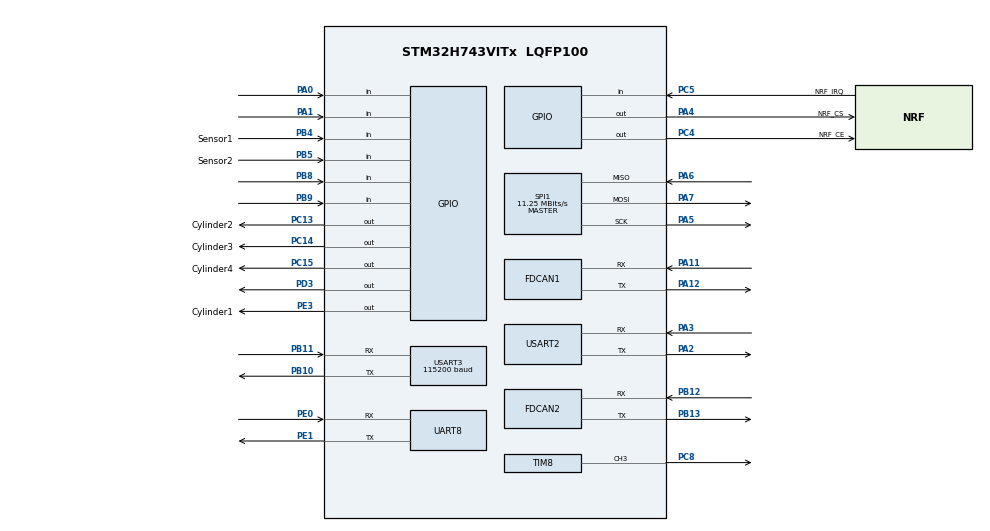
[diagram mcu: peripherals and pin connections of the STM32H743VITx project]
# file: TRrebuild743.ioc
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CORTEX_M7.CPU_DCache=Disabled
CORTEX_M7.CPU_ICache=Disabled
Dma.Request0=UART8_RX
Dma.Request1=TIM8_CH3
Dma.Request2=USART2_RX
Dma.TIM8_CH3.1.Direction=DMA_MEMORY_TO_PERIPH
Dma.TIM8_CH3.1.EventEnable=DISABLE
Dma.TIM8_CH3.1.FIFOMode=DMA_FIFOMODE_DISABLE
Dma.TIM8_CH3.1.Instance=DMA1_Stream1
Dma.TIM8_CH3.1.MemDataAlignment=DMA_MDATAALIGN_HALFWORD
Dma.TIM8_CH3.1.MemInc=DMA_MINC_ENABLE
Dma.TIM8_CH3.1.Mode=DMA_CIRCULAR
Dma.TIM8_CH3.1.PeriphDataAlignment=DMA_PDATAALIGN_HALFWORD
Dma.TIM8_CH3.1.PeriphInc=DMA_PINC_DISABLE
Dma.TIM8_CH3.1.Polarity=HAL_DMAMUX_REQ_GEN_RISING
Dma.TIM8_CH3.1.Priority=DMA_PRIORITY_HIGH
Dma.TIM8_CH3.1.RequestNumber=1
Dma.TIM8_CH3.1.SignalID=NONE
Dma.TIM8_CH3.1.SyncEnable=DISABLE
Dma.TIM8_CH3.1.SyncPolarity=HAL_DMAMUX_SYNC_NO_EVENT
Dma.TIM8_CH3.1.SyncRequestNumber=1
Dma.TIM8_CH3.1.SyncSignalID=NONE
Dma.UART8_RX.0.Direction=DMA_PERIPH_TO_MEMORY
Dma.UART8_RX.0.EventEnable=DISABLE
Dma.UART8_RX.0.FIFOMode=DMA_FIFOMODE_DISABLE
Dma.UART8_RX.0.Instance=DMA1_Stream0
Dma.UART8_RX.0.MemDataAlignment=DMA_MDATAALIGN_BYTE
Dma.UART8_RX.0.MemInc=DMA_MINC_ENABLE
Dma.UART8_RX.0.Mode=DMA_CIRCULAR
Dma.UART8_RX.0.PeriphDataAlignment=DMA_PDATAALIGN_BYTE
Dma.UART8_RX.0.PeriphInc=DMA_PINC_DISABLE
Dma.UART8_RX.0.Polarity=HAL_DMAMUX_REQ_GEN_RISING
Dma.UART8_RX.0.Priority=DMA_PRIORITY_LOW
Dma.UART8_RX.0.RequestNumber=1
Dma.UART8_RX.0.SignalID=NONE
Dma.UART8_RX.0.SyncEnable=DISABLE
Dma.UART8_RX.0.SyncPolarity=HAL_DMAMUX_SYNC_NO_EVENT
Dma.UART8_RX.0.SyncRequestNumber=1
Dma.UART8_RX.0.SyncSignalID=NONE
Dma.USART2_RX.2.Direction=DMA_PERIPH_TO_MEMORY
Dma.USART2_RX.2.EventEnable=DISABLE
Dma.USART2_RX.2.FIFOMode=DMA_FIFOMODE_DISABLE
Dma.USART2_RX.2.Instance=DMA1_Stream2
Dma.USART2_RX.2.MemDataAlignment=DMA_MDATAALIGN_BYTE
Dma.USART2_RX.2.MemInc=DMA_MINC_ENABLE
Dma.USART2_RX.2.Mode=DMA_CIRCULAR
Dma.USART2_RX.2.PeriphDataAlignment=DMA_PDATAALIGN_BYTE
Dma.USART2_RX.2.PeriphInc=DMA_PINC_DISABLE
Dma.USART2_RX.2.Polarity=HAL_DMAMUX_REQ_GEN_RISING
Dma.USART2_RX.2.Priority=DMA_PRIORITY_LOW
Dma.USART2_RX.2.RequestNumber=1
Dma.USART2_RX.2.SignalID=NONE
Dma.USART2_RX.2.SyncEnable=DISABLE
Dma.USART2_RX.2.SyncPolarity=HAL_DMAMUX_SYNC_NO_EVENT
Dma.USART2_RX.2.SyncRequestNumber=1
Dma.USART2_RX.2.SyncSignalID=NONE
FDCAN1.DataTimeSeg1=15
FDCAN1.DataTimeSeg2=4
FDCAN1.NominalSyncJumpWidth=1
FDCAN1.NominalTimeSeg1=15
FDCAN1.NominalTimeSeg2=4
FDCAN1.RxFifo0ElmtsNbr=32
FDCAN1.StdFiltersNbr=1
FDCAN1.TxBuffersNbr=0
FDCAN1.TxFifoQueueElmtsNbr=16
FDCAN2.AutoRetransmission=DISABLE
FDCAN2.DataTimeSeg1=15
FDCAN2.DataTimeSeg2=4
FDCAN2.MessageRAMOffset=0x304
FDCAN2.NominalTimeSeg1=15
FDCAN2.NominalTimeSeg2=4
FDCAN2.RxFifo1ElmtsNbr=32
FDCAN2.StdFiltersNbr=2
FDCAN2.TxFifoQueueElmtsNbr=16
FREERTOS.INCLUDE_xTaskGetHandle=1
FREERTOS.Tasks01=defaultTask,24,128,StartDefaultTask,Default,NULL,Dynamic,NULL,NULL;Robot,24,256,RobotTask,Default,NULL,Dynamic,NULL,NULL;manualmove,8,256,manual_move,Default,NULL,Dynamic,NULL,NULL;error_detector,8,128,errordetector,Default,NULL,Dynamic,NULL,NULL;debug_msg,8,128,send_debug_msg,Default,NULL,Dynamic,NULL,NULL
FREERTOS.configTOTAL_HEAP_SIZE=0x2C000
Mcu.Family=STM32H7
Mcu.Name=STM32H743VITx
Mcu.Package=LQFP100
NVIC.DMA1_Stream0_IRQn=true\:5\:0\:false\:false\:true\:true\:false\:true
NVIC.DMA1_Stream1_IRQn=true\:5\:0\:false\:false\:true\:true\:false\:true
NVIC.DMA1_Stream2_IRQn=true\:5\:0\:false\:false\:true\:true\:false\:true
NVIC.FDCAN1_IT0_IRQn=true\:5\:0\:true\:false\:true\:true\:true\:true
NVIC.FDCAN2_IT0_IRQn=true\:5\:0\:false\:false\:true\:true\:true\:true
NVIC.PriorityGroup=NVIC_PRIORITYGROUP_4
NVIC.TIM6_DAC_IRQn=true\:5\:0\:true\:false\:true\:true\:true\:true
NVIC.TIM7_IRQn=true\:1\:0\:true\:false\:true\:false\:true\:true
NVIC.TIM8_BRK_TIM12_IRQn=true\:5\:0\:false\:false\:true\:true\:true\:true
NVIC.TIM8_TRG_COM_TIM14_IRQn=true\:5\:0\:false\:false\:true\:false\:false\:true
NVIC.TIM8_UP_TIM13_IRQn=true\:5\:0\:false\:false\:true\:true\:true\:true
NVIC.TimeBase=TIM8_TRG_COM_TIM14_IRQn
NVIC.TimeBaseIP=TIM14
NVIC.UART8_IRQn=true\:5\:0\:false\:false\:true\:true\:true\:true
NVIC.USART3_IRQn=true\:5\:0\:false\:false\:true\:true\:true\:true
PA0.GPIO_PuPd=GPIO_PULLDOWN
PA0.Signal=GPIO_Input
PA1.GPIO_PuPd=GPIO_PULLDOWN
PA1.Signal=GPIO_Input
PA11.GPIO_PuPd=GPIO_PULLUP
PA11.GPIO_Speed=GPIO_SPEED_FREQ_VERY_HIGH
PA11.Mode=FDCAN_Activate
PA11.Signal=FDCAN1_RX
PA12.GPIO_PuPd=GPIO_PULLUP
PA12.GPIO_Speed=GPIO_SPEED_FREQ_VERY_HIGH
PA12.Mode=FDCAN_Activate
PA12.Signal=FDCAN1_TX
PA13\ (JTMS/SWDIO).Mode=Serial_Wire
PA13\ (JTMS/SWDIO).Signal=DEBUG_JTMS-SWDIO
PA14\ (JTCK/SWCLK).Mode=Serial_Wire
PA14\ (JTCK/SWCLK).Signal=DEBUG_JTCK-SWCLK
PA2.Mode=Asynchronous
PA2.Signal=USART2_TX
PA3.Mode=Asynchronous
PA3.Signal=USART2_RX
PA4.GPIO_Label=NRF_CS
PA4.GPIO_PuPd=GPIO_PULLUP
PA4.GPIO_Speed=GPIO_SPEED_FREQ_HIGH
PA4.Signal=GPIO_Output
PA5.GPIO_PuPd=GPIO_NOPULL
PA5.GPIO_Speed=GPIO_SPEED_FREQ_VERY_HIGH
PA5.Mode=Full_Duplex_Master
PA5.Signal=SPI1_SCK
PA6.GPIO_PuPd=GPIO_NOPULL
PA6.GPIO_Speed=GPIO_SPEED_FREQ_VERY_HIGH
PA6.Mode=Full_Duplex_Master
PA6.Signal=SPI1_MISO
PA7.GPIO_PuPd=GPIO_NOPULL
PA7.GPIO_Speed=GPIO_SPEED_FREQ_VERY_HIGH
PA7.Mode=Full_Duplex_Master
PA7.Signal=SPI1_MOSI
PB10.Mode=Asynchronous
PB10.Signal=USART3_TX
PB11.Mode=Asynchronous
PB11.Signal=USART3_RX
PB12.GPIO_PuPd=GPIO_PULLUP
PB12.GPIO_Speed=GPIO_SPEED_FREQ_VERY_HIGH
PB12.Mode=FDCAN_Activate
PB12.Signal=FDCAN2_RX
PB13.GPIO_PuPd=GPIO_PULLUP
PB13.GPIO_Speed=GPIO_SPEED_FREQ_VERY_HIGH
PB13.Mode=FDCAN_Activate
PB13.Signal=FDCAN2_TX
PB4\ (NJTRST).GPIO_Label=Sensor1
PB4\ (NJTRST).GPIO_PuPd=GPIO_PULLDOWN
PB4\ (NJTRST).Signal=GPIO_Input
PB5.GPIO_Label=Sensor2
PB5.GPIO_PuPd=GPIO_PULLDOWN
PB5.Signal=GPIO_Input
PB8.GPIO_PuPd=GPIO_PULLDOWN
PB8.Signal=GPIO_Input
PB9.GPIO_PuPd=GPIO_PULLDOWN
PB9.Signal=GPIO_Input
PC13.GPIO_Label=Cylinder2
PC13.GPIO_PuPd=GPIO_PULLUP
PC13.Signal=GPIO_Output
PC14-OSC32_IN\ (OSC32_IN).GPIO_Label=Cylinder3
PC14-OSC32_IN\ (OSC32_IN).GPIO_PuPd=GPIO_PULLUP
PC14-OSC32_IN\ (OSC32_IN).Signal=GPIO_Output
PC15-OSC32_OUT\ (OSC32_OUT).GPIO_Label=Cylinder4
PC15-OSC32_OUT\ (OSC32_OUT).GPIO_PuPd=GPIO_PULLUP
PC15-OSC32_OUT\ (OSC32_OUT).Signal=GPIO_Output
PC4.GPIO_Label=NRF_CE
PC4.GPIO_PuPd=GPIO_PULLUP
PC4.GPIO_Speed=GPIO_SPEED_FREQ_HIGH
PC4.Signal=GPIO_Output
PC5.GPIO_Label=NRF_IRQ
PC5.Signal=GPIO_Input
PC8.GPIO_Speed=GPIO_SPEED_FREQ_VERY_HIGH
PC8.Signal=S_TIM8_CH3
PD3.GPIO_PuPd=GPIO_PULLDOWN
PD3.GPIO_Speed=GPIO_SPEED_FREQ_HIGH
PD3.Signal=GPIO_Output
PE0.Mode=Asynchronous
PE0.Signal=UART8_RX
PE1.Mode=Asynchronous
PE1.Signal=UART8_TX
PE3.GPIO_Label=Cylinder1
PE3.GPIO_PuPd=GPIO_PULLUP
PE3.Signal=GPIO_Output
PH0-OSC_IN\ (PH0).Mode=HSE-External-Oscillator
PH0-OSC_IN\ (PH0).Signal=RCC_OSC_IN
PH1-OSC_OUT\ (PH1).Mode=HSE-External-Oscillator
PH1-OSC_OUT\ (PH1).Signal=RCC_OSC_OUT
ProjectManager.HeapSize=0x3F000
ProjectManager.StackSize=0x2000
ProjectManager.TargetToolchain=MDK-ARM V5.27
RCC.ADCFreq_Value=90000000
RCC.APB1Freq_Value=120000000
RCC.APB2Freq_Value=120000000
RCC.APB3Freq_Value=120000000
RCC.APB4Freq_Value=120000000
RCC.CortexFreq_Value=480000000
RCC.D1PPRE=RCC_APB3_DIV2
RCC.D2PPRE1=RCC_APB1_DIV2
RCC.D2PPRE2=RCC_APB2_DIV2
RCC.D3PPRE=RCC_APB4_DIV2
RCC.DIVM1=5
RCC.DIVM2=5
RCC.DIVN1=192
RCC.DIVN2=90
RCC.DIVP2=5
RCC.DIVQ1=48
RCC.HCLKFreq_Value=240000000
RCC.HPRE=RCC_HCLK_DIV2
RCC.PLL2FRACN=0
RCC.PLL3FRACN=0
RCC.PLLFRACN=0
RCC.PLLSourceVirtual=RCC_PLLSOURCE_HSE
RCC.SPI123CLockSelection=RCC_SPI123CLKSOURCE_PLL2
RCC.SYSCLKFreq_VALUE=480000000
RCC.SYSCLKSource=RCC_SYSCLKSOURCE_PLLCLK
RCC.USBFreq_Value=20000000
SH.S_TIM8_CH3.0=TIM8_CH3,PWM Generation3 CH3
SPI1.BaudRatePrescaler=SPI_BAUDRATEPRESCALER_8
SPI1.CalculateBaudRate=11.25 MBits/s
SPI1.DataSize=SPI_DATASIZE_8BIT
SPI1.Direction=SPI_DIRECTION_2LINES
SPI1.Mode=SPI_MODE_MASTER
SPI1.VirtualType=VM_MASTER
TIM6.Period=9999
TIM6.Prescaler=239
TIM7.Period=100-1
TIM7.Prescaler=240-1
TIM8.AutoReloadPreload=TIM_AUTORELOAD_PRELOAD_DISABLE
TIM8.Channel-PWM\ Generation3\ CH3=TIM_CHANNEL_3
TIM8.Period=75-1
TIM8.Prescaler=4-1
USART2.VirtualMode-Asynchronous=VM_ASYNC
USART3.BaudRate=115200
USART3.VirtualMode-Asynchronous=VM_ASYNC
VP_FREERTOS_VS_CMSIS_V2.Mode=CMSIS_V2
VP_SYS_VS_tim14.Mode=TIM14
VP_TIM6_VS_ClockSourceINT.Mode=Enable_Timer
VP_TIM7_VS_ClockSourceINT.Mode=Enable_Timer
VP_TIM8_VS_ClockSourceINT.Mode=Internal
board=custom

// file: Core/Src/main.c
/* USER CODE BEGIN Header */
/**
  ******************************************************************************
  * @file           : main.c
  * @brief          : Main program body
  ******************************************************************************
  * @attention
  *
  * <h2><center>&copy; Copyright (c) 2022 STMicroelectronics.
  * All rights reserved.</center></h2>
  *
  * This software component is licensed by ST under Ultimate Liberty license
  * SLA0044, the "License"; You may not use this file except in compliance with
  * the License. You may obtain a copy of the License at:
  *                             www.st.com/SLA0044
  *
  ******************************************************************************
  */
/* USER CODE END Header */
#include "main.h"
#include "cmsis_os.h"
#include "dma.h"
#include "fdcan.h"
#include "spi.h"
#include "tim.h"
#include "usart.h"
#include "gpio.h"

/* USER CODE BEGIN Includes */
#include "Elmo_fdcan.h"
#include "nrf.h"
#include "Resolve.h"
#include "fdcan_bsp.h"
#include "my_robot.h"
#include "math.h"
#include "usart.h"
#include "move.h"
#include "Remote_Control.h"
#include "arm_math.h"
#include "HMI.h"
#include "Tinn.h"
#include "rgb.h"
#include "GM6020.h"
#include "VESC_CAN.h"
#include "Ann.h"
#include "steering_wheel.h"
/* USER CODE END Includes */

/* USER CODE BEGIN PV */
extern Kal_Filter kal_velocity_x,kal_velocity_y;
extern float dX;
extern float dY;
extern float dZ;
Ort debug;
float last_pos_x=0,last_pos_y=0;
uint8_t rxtemp=0;
int rocker[4];
uint8_t turret_buffer[8];
uint8_t dma_buffer[30]={0};
uint8_t tof_buffer[10]={0};
short tof_read;
uint8_t Rx_buffer[16]={0};
uint8_t huart3_rxbuffer[16]={0};
Ort current_acceration;
Ort current_speed;
Ort current_chassis_speed,avg_speed;
Ort current_speed_before_filt;
Ort current_pos={.x=6,.y=0.41f};
Ort correction_value={.x=6,.y=0.335f};
uint8_t cmd_feedback[8];
Ort pos_buffer[9];
Ort speed_buffer[6];
Ort target_relative_pos;
int global_clock;
int speed_clock;
uint32_t speed_timer=0;
float vx[10],vy[10],ababa;
Ort pos_log[50];
uint8_t pos_reset=0;
ANN_PID_handle velocity_nn_x={.network.input_2_hidden.mat={0.07388,0,0.102044,0,0,0.102044,0,0.0574135,0,0,0.0574135,0,0.102044,0,0,0.10204422,0,-0.0063,0},.network.hidden_2_output.mat={0.073885,0,0.102044,0,0.0574135,0,0.10204422,0,-0.006343383}}
,velocity_nn_y={.network.input_2_hidden.mat={0.07388,0,0.102044,0,0,0.102044,0,0.0574135,0,0,0.0574135,0,0.102044,0,0,0.10204422,0,-0.0063,0},.network.hidden_2_output.mat={0.073885,0,0.102044,0,0.0574135,0,0.10204422,0,-0.006343383}};
Ort raw_correction_value;
uint8_t block_color=0;
uint8_t communciation_error_counter=0;
extern uint8_t get_block_flag;
//int package_recieve=0,package_valid=0;
//int start_nbr=0;

/* USER CODE END PV */

void SystemClock_Config(void);
void MX_FREERTOS_Init(void);
/* USER CODE BEGIN PFP */
void acceration_limit(void);
void speed_cal(void);
void update_target_info(uint8_t *data);
void DMA_recieve(void);
void executive_auto_move(void);
void send_log(uint8_t ID,float data1,float data2,float data3,float data4,UART_HandleTypeDef *uart);
void send_msg(void);
void send_init_msg(UART_HandleTypeDef *uart,uint8_t ID);
/* USER CODE END PFP */

int main(void)
{

  /* MCU Configuration--------------------------------------------------------*/

  /* Reset of all peripherals, Initializes the Flash interface and the Systick. */
  HAL_Init();

  /* Configure the system clock */
  SystemClock_Config();

  /* Initialize all configured peripherals */
  MX_GPIO_Init();
  MX_DMA_Init();
  MX_SPI1_Init();
  MX_TIM6_Init();
  MX_TIM7_Init();
  MX_UART8_Init();
  MX_TIM8_Init();
  MX_FDCAN1_Init();
  MX_FDCAN2_Init();
  MX_USART3_UART_Init();
  MX_USART2_UART_Init();
  /* USER CODE BEGIN 2 */
    nrf_init();
    HAL_Delay(20);
    FDCAN1_Init(&hfdcan1);
    HAL_Delay(200);
    HAL_TIM_Base_Start_IT(&htim7);
    HAL_Delay(200);
    FDCAN2_Init(&hfdcan2);
    HAL_Delay(20);
    HAL_UART_Receive_DMA(&huart8,dma_buffer,30);
    HAL_UART_Receive_IT(&huart3,huart3_rxbuffer,16);
    HAL_UART_Receive_DMA(&huart2,tof_buffer,10);
    extern uint16_t RGB_DEFAULT[2];
    RGB_DEFAULT[0]=0;
    RGB_Color(&htim8,TIM_CHANNEL_3,RGB_DEFAULT,0.2f);
    RGB_Init(&htim8,TIM_CHANNEL_3);

    for(int i=0;i<10;i++)
    {
        if(HAL_GPIO_ReadPin(GPIOB,GPIO_PIN_4))
        {
            send_init_msg(&huart8,0x02);
        }
        else
        {
            send_init_msg(&huart8,0x03);
        }
    HAL_Delay(10);
    }
    //__disable_fault_irq();//????????

    for(int i=0;i<10;i++)
    {

        HAL_Delay(10);
    }
    HAL_TIM_Base_Start_IT(&htim6);
    extern uint8_t block_num;
    //float
    //tnn_buffer1_1[12]={-0.416729,-0.337441,0.190049,0.40271,0.229096,0.463848,0.240863,0.377448,-0.0322686,0.223719,0.123895,0.563927},
    //tnn_buffer1_2[2]={-0.257041,0.419105},
    //tnn_buffer2_1[12]={0.13623,-0.440966,0.308962,0.0377088,0.434576,0.490001,0.0025015,0.445981,-0.0441973,0.395057,0.0753355,0.442013},
    //tnn_buffer2_2[2]={0.326608,-0.0178685};
    block_num=2;
    Ort base={.x=8,.y=6};
    update_barrier(1,base,0.7f,0);
    base.x=4;
    base.y=6;
    update_barrier(12,base,0.7f,0);
    ANN_pid_init(&velocity_nn_x);
    ANN_pid_init(&velocity_nn_y);
    r_correction_value=correction_value;
    hmi_init(&huart3);

  /* USER CODE END 2 */

  /* Init scheduler */
  osKernelInitialize();  /* Call init function for freertos objects (in freertos.c) */
  MX_FREERTOS_Init();
  /* Start scheduler */
  osKernelStart();

  /* We should never get here as control is now taken by the scheduler */
  /* Infinite loop */
  while (1)
  {

  }
}

void SystemClock_Config(void)
{
  RCC_OscInitTypeDef RCC_OscInitStruct = {0};
  RCC_ClkInitTypeDef RCC_ClkInitStruct = {0};

  /** Supply configuration update enable
  */
  HAL_PWREx_ConfigSupply(PWR_LDO_SUPPLY);
  /** Configure the main internal regulator output voltage
  */
  __HAL_PWR_VOLTAGESCALING_CONFIG(PWR_REGULATOR_VOLTAGE_SCALE0);

  while(!__HAL_PWR_GET_FLAG(PWR_FLAG_VOSRDY)) {}
  /** Macro to configure the PLL clock source
  */
  __HAL_RCC_PLL_PLLSOURCE_CONFIG(RCC_PLLSOURCE_HSE);
  /** Initializes the RCC Oscillators according to the specified parameters
  * in the RCC_OscInitTypeDef structure.
  */
  RCC_OscInitStruct.OscillatorType = RCC_OSCILLATORTYPE_HSE;
  RCC_OscInitStruct.HSEState = RCC_HSE_ON;
  RCC_OscInitStruct.PLL.PLLState = RCC_PLL_ON;
  RCC_OscInitStruct.PLL.PLLSource = RCC_PLLSOURCE_HSE;
  RCC_OscInitStruct.PLL.PLLM = 5;
  RCC_OscInitStruct.PLL.PLLN = 192;
  RCC_OscInitStruct.PLL.PLLP = 2;
  RCC_OscInitStruct.PLL.PLLQ = 48;
  RCC_OscInitStruct.PLL.PLLR = 2;
  RCC_OscInitStruct.PLL.PLLRGE = RCC_PLL1VCIRANGE_2;
  RCC_OscInitStruct.PLL.PLLVCOSEL = RCC_PLL1VCOWIDE;
  RCC_OscInitStruct.PLL.PLLFRACN = 0;
  if (HAL_RCC_OscConfig(&RCC_OscInitStruct) != HAL_OK)
  {
    Error_Handler();
  }
  /** Initializes the CPU, AHB and APB buses clocks
  */
  RCC_ClkInitStruct.ClockType = RCC_CLOCKTYPE_HCLK|RCC_CLOCKTYPE_SYSCLK
                              |RCC_CLOCKTYPE_PCLK1|RCC_CLOCKTYPE_PCLK2
                              |RCC_CLOCKTYPE_D3PCLK1|RCC_CLOCKTYPE_D1PCLK1;
  RCC_ClkInitStruct.SYSCLKSource = RCC_SYSCLKSOURCE_PLLCLK;
  RCC_ClkInitStruct.SYSCLKDivider = RCC_SYSCLK_DIV1;
  RCC_ClkInitStruct.AHBCLKDivider = RCC_HCLK_DIV2;
  RCC_ClkInitStruct.APB3CLKDivider = RCC_APB3_DIV2;
  RCC_ClkInitStruct.APB1CLKDivider = RCC_APB1_DIV2;
  RCC_ClkInitStruct.APB2CLKDivider = RCC_APB2_DIV2;
  RCC_ClkInitStruct.APB4CLKDivider = RCC_APB4_DIV2;

  if (HAL_RCC_ClockConfig(&RCC_ClkInitStruct, FLASH_LATENCY_4) != HAL_OK)
  {
    Error_Handler();
  }
}

/* USER CODE BEGIN 4 */
int judge_sign(double num)
{
    if(num>0)
        return 1;
    if(num<0)
        return -1;
    if(num==0)
        return 0;
    return 0;
}

void acceration_limit()
{
    static float lastdx=0,lastdy=0,mode[2]={0.03f,0.07f};
    float current_acceration;

    current_acceration=sqrtf((dX-lastdx)*(dX-lastdx)+(dY-lastdy)*(dY-lastdy));
    if(((lastdx*lastdx+lastdy*lastdy)>0.0004f||(dX*dX+dY*dY)>0.0004f)&&flags[auto_drive_status]!=moving)
    {
        if(current_acceration>mode[Read_Button(22)])
        {
            dX=judge_sign(dX-lastdx)*mode[Read_Button(22)]*fabs(dX-lastdx)/current_acceration+lastdx;
            dY=judge_sign(dY-lastdy)*mode[Read_Button(22)]*fabs(dY-lastdy)/current_acceration+lastdy;
        }
    }
        lastdx=dX;
        lastdy=dY;
    return;
}

void send_msg(void)
{
    uint8_t msg_buffer[30];
    msg_buffer[0]='?';
    msg_buffer[1]='!';
    msg_buffer[2]=0x05;
    int ax,ay,az;
    ax=gyro.x+r_correction_value.x*1000;
    ay=gyro.y+r_correction_value.y*1000;
    memcpy(msg_buffer+3,&ax,4);
    memcpy(msg_buffer+7,&ay,4);
    az=(int)(current_pos.z*1000);
    if(az<0)
        az=360000+az;
    memcpy(msg_buffer+11,&az,4);
    msg_buffer[15]='!';
    HAL_UART_Transmit(&huart8,msg_buffer,16,20);
    //HAL_UART_Transmit(&huart3,msg_buffer,16,200);
    return;
}

void send_init_msg(UART_HandleTypeDef *uart,uint8_t ID)
{
    uint8_t msg_buffer[16];
    msg_buffer[0]='?';
    msg_buffer[1]='!';
    msg_buffer[2]=ID;
//    int ax,ay,az;
//    ax=data1*1000;
//    ay=data2*1000;
//    memcpy(msg_buffer+3,&ax,4);
//    memcpy(msg_buffer+7,&ay,4);
//    az=(int)(gyro.z*1000);
//    memcpy(msg_buffer+11,&az,4);
    msg_buffer[15]='!';
    HAL_UART_Transmit(uart,msg_buffer,16,200);
    return;
}

void executive_auto_move(void)
{
    double distance,pid_distance;
    distance=sqrtf((current_pos.x-pos_plan[global_clock].x)*(current_pos.x-pos_plan[global_clock].x)+(current_pos.y-pos_plan[global_clock].y)*(current_pos.y-pos_plan[global_clock].y));
    pid_distance=-Pid_Run(&pid_pos,0,distance);
    dX=(pos_plan[global_clock].x-current_pos.x)/distance*pid_distance+speed_plan[global_clock].x;
    dY=(pos_plan[global_clock].y-current_pos.y)/distance*pid_distance+speed_plan[global_clock].y;
    return;
}

void send_log(uint8_t ID,float data1,float data2,float data3,float data4,UART_HandleTypeDef *uart)
{
    uint8_t abaaba[18];
    abaaba[0]=0x02;
    abaaba[17]=ID;
    memcpy(abaaba+1,&data1,4);
    memcpy(abaaba+5,&data2,4);
    memcpy(abaaba+9,&data3,4);
    memcpy(abaaba+13,&data4,4);
    HAL_UART_Transmit(uart,abaaba,18,1);
    return;
}

void send_log2(float data1,float data2,float data3,float data4,UART_HandleTypeDef *uart)
{
    uint8_t abaaba[20];
    memcpy(abaaba,&data1,4);
    memcpy(abaaba+4,&data2,4);
    memcpy(abaaba+8,&data3,4);
    memcpy(abaaba+12,&data4,4);
    abaaba[19]=0x7f;
    abaaba[18]=0x80;
    abaaba[17]=0x00;
    abaaba[16]=0x00;
    HAL_UART_Transmit(uart,abaaba,20,1);
    return;
}

void send_log3(float data1,float data2,float data3,uint8_t id,UART_HandleTypeDef *uart)
{
    uint8_t msg_buffer[16];
    int ax,ay,az;
    msg_buffer[0]='?';
    msg_buffer[1]='!';
    msg_buffer[2]=id;
    ax=data1*1000;
    ay=data2*1000;
    memcpy(msg_buffer+3,&ax,4);
    memcpy(msg_buffer+7,&ay,4);
    az=(int)(data3*1000);
    memcpy(msg_buffer+11,&az,4);
    msg_buffer[15]='!';

    HAL_UART_Transmit(uart,msg_buffer,16,1);
    return;
}

void speed_cal(void)
{
//    static float lastx[2]={0},lasty[2]={0};
//    static int last_gyrox=0,last_gyroy=0;

//    current_acceration.x=(current_speed.x-lastsx)/0.001f;
//    current_acceration.y=(current_speed.y-lastsy)/0.001f;

//    lastsx=current_speed.x;
//    lastsy=current_speed.y;

//    current_pos.x=current_pos.x+((float)(gyro.x-last_gyrox)/1000.0f)*arm_cos_f32(-correction_value.z*3.1415926f/180.0f)+((float)(gyro.y-last_gyroy)/1000.0f)*(-arm_sin_f32(-correction_value.z*3.1415926f/180.0f));
//    current_pos.y=current_pos.y+((float)(gyro.x-last_gyrox)/1000.0f)*arm_sin_f32(-correction_value.z*3.1415926f/180.0f)+((float)(gyro.y-last_gyroy)/1000.0f)*(arm_cos_f32(-correction_value.z*3.1415926f/180.0f));
    current_pos.x=(float)gyro.x/1000.0f+correction_value.x;
    current_pos.y=(float)gyro.y/1000.0f+correction_value.y;
    current_pos.z=gyro.z+correction_value.z;
//    last_gyrox=gyro.x;
//    last_gyroy=gyro.y;
    while(fabs(current_pos.z)>180)
    {
        if(current_pos.z>0)
            current_pos.z-=360.0f;
        else
            current_pos.z+=360.0f;
    }

    for(int i=4;i>=0;i--)
    {
        vx[i+1]=vx[i];
        vy[i+1]=vy[i];
    }
    vx[0]=current_pos.x;
    vy[0]=current_pos.y;
//    current_speed.x=(vx[0]+vx[1]+vx[2]-vx[3]-vx[4]-vx[5])/0.045f;
//    current_speed.y=(vy[0]+vy[1]+vy[2]-vy[3]-vy[4]-vy[5])/0.045f;
    if(speed_timer==0)
        return;
    current_speed_before_filt.x=(vx[0]-vx[1])/(speed_timer/10000.0f);
    current_speed_before_filt.y=(vy[0]-vy[1])/(speed_timer/10000.0f);
    avg_speed.x=0.99f*avg_speed.x+0.01f*current_speed_before_filt.x;
    current_speed.x=Kalman_Filter(&kal_velocity_x,current_speed_before_filt.x);
    current_speed.y=Kalman_Filter(&kal_velocity_y,current_speed_before_filt.y);
    avg_speed.y=0.99f*avg_speed.y+0.01f*current_speed.x;
    speed_timer=0;
    current_chassis_speed.x=current_speed.x*arm_cos_f32(current_pos.z*3.1415926f/180.0f)-current_speed.y*arm_sin_f32(current_pos.z*3.1415926f/180.0f);
    current_chassis_speed.y=current_speed.x*arm_sin_f32(current_pos.z*3.1415926f/180.0f)+current_speed.y*arm_cos_f32(current_pos.z*3.1415926f/180.0f);

    //send_log(0x01,vx[time],vy[time],current_speed.x,current_speed.y,&huart3);

    if(gyro.error_counter<1000)
        gyro.error_counter++;
    return;
}

void update_target_info(uint8_t *data)
{
    int temp[3];
    int deg=0;
    Ort temp1;
    uint8_t temp2,cmd,id;
    cmd=data[2];
    barrier *base;
    static uint8_t fifo[10];
    uint8_t counter[4]={0};

    if(cmd>0&&cmd<6)
    {

        memcpy(temp,data+3,4);
        memcpy(temp+1,data+7,4);
        temp2=data[11];
        if((int8_t)data[12]!=90)
        {
            deg=-(int8_t)data[12]+current_pos.z;
            if(deg>90)
            {
                deg-=180;
            }
            if(deg<-90)
            {
                deg+=180;
            }
        }
        else
        {
            deg=361;
        }
        if(fabs(temp[0]/1000.0f)>10.5f||fabs(temp[1]/1000.0f)>10.5f)
        {
            return;
        }
        cmd=7-cmd;
        temp1.x=(float)temp[0]/1000.0f;
        temp1.y=(float)(temp[1])/1000.0f;
        temp1.z=temp2;
        //temp1=coordinate_transform(temp1,pos_log[19]);
        if(block_num==cmd)
        {
            block_color=temp2;
        }
        if(cmd>=block_num)
            update_barrier(cmd,temp1,0.5f-(cmd-2)*0.075f,deg);
    }
    else if(cmd==6)
    {
        memcpy(temp,data+3,4);
        memcpy(temp+1,data+7,4);
        temp2=data[11];
        temp1.x=(float)(temp[0])/1000.0f;
        temp1.y=(float)(temp[1])/1000.0f;
//        temp1.x-=pos_log[0].x-pos_log[5].x;
//        temp1.y-=pos_log[0].y-pos_log[5].y;
        temp1.z=temp2;
        if(temp1.x>11||temp1.y>9||temp1.x<5||temp1.y<3)
            return;
        //send_debug_msg(&huart8,temp1.x,temp1.y,0x06);
        //temp1=coordinate_transform(temp1,pos_log[5]);
        update_barrier(1,temp1,0.7,0);
    }
    else if(cmd==7)
    {
        memcpy(temp,data+3,4);
        memcpy(temp+1,data+7,4);
        id=data[11];
        temp1.x=(float)(temp[0])/1000.0f;
        temp1.y=(float)(temp[1])/1000.0f;
        if(fabs(temp1.x)>14||fabs(temp1.y)>14||temp1.x<0.5f||temp1.y<0.5f)
            return;
        update_check_point(temp1,id);
    }
    else if(cmd==8&&final_point_lock==0)
    {
        base=find_barrier(1);
        memcpy(temp,data+3,4);
        memcpy(temp+1,data+7,4);
        temp1.x=(float)(temp[0])/1000.0f;
        temp1.y=(float)(temp[1])/1000.0f;
        if(fabs(temp1.x)>14||fabs(temp1.y)>14||temp1.x<0.5f||temp1.y<0.5f)
            return;
        final_point=temp1;
        final_point.z=-atan2f(base->location.x-temp1.x,base->location.y-temp1.y)*180.0f/3.1415926f;
    }
    else if(cmd==9)
    {
        if(data[3]<=3)
        {
            for(int i=9;i>0;i--)
            {
                fifo[i]=fifo[i-1];
            }
            fifo[0]=data[3];
            for(int i=0;i<4;i++)
                counter[i]=0;
            for(int i=0;i<10;i++)
            {
                counter[fifo[i]]++;
            }
            uint8_t biggest=0;
            for(int i=0;i<4;i++)
            {
                if(counter[i]>counter[biggest])
                {
                    biggest=i;
                }
            }
            block_color=biggest;
        }
    }
    else if(cmd>=10&&cmd<=14)
    {
        memcpy(temp,data+3,4);
        memcpy(temp+1,data+7,4);
        temp2=data[11];
        if((int8_t)data[12]!=90)
        {
            deg=-(int8_t)data[12]+current_pos.z;
            if(deg>90)
            {
                deg-=180;
            }
            if(deg<-90)
            {
                deg+=180;
            }
        }
        else
        {
            deg=361;
        }
        if((temp[0]/1000.0f)>10.5f||fabs(temp[1]/1000.0f)>10.5f)
        {
            return;
        }
        cmd=21-cmd;
        temp1.x=(float)temp[0]/1000.0f;
        temp1.y=(float)(temp[1])/1000.0f;
        temp1.z=temp2;
        if(block_num==cmd)
        {
            block_color=temp2;
        }
        //temp1=coordinate_transform(temp1,pos_log[19]);
        if(cmd>=block_num)
            update_barrier(cmd,temp1,0.5f-(cmd-2-5)*0.075f,deg);
    }
    else if(cmd==15)
    {
        memcpy(temp,data+3,4);
        memcpy(temp+1,data+7,4);
        temp2=data[11];
        temp1.x=(float)(temp[0])/1000.0f;
        temp1.y=(float)(temp[1])/1000.0f;
//        temp1.x-=pos_log[0].x-pos_log[5].x;
//        temp1.y-=pos_log[0].y-pos_log[5].y;
        temp1.z=temp2;
        if(temp1.x>7||temp1.y>9||temp1.x<1||temp1.y<3)
            return;
        //send_debug_msg(&huart8,temp1.x,temp1.y,0x06);
        //temp1=coordinate_transform(temp1,pos_log[5]);
        update_barrier(12,temp1,0.7,0);
    }
//    else if(cmd==99)
//    {
//        memcpy(temp,data+3,4);
//        memcpy(temp+1,data+7,4);
//        if(temp[0]>10000||temp[0]<=0)
//            return;
//        if(start_nbr==0)
//            start_nbr=temp[0];
//        package_recieve=temp[0]-start_nbr+1;
//        package_valid++;
//        send_log3(temp[0],(float)package_valid/(float)package_recieve,0,99,&huart8);
//    }
    else if(cmd==114)
    {
        memcpy(temp,data+3,4);
        memcpy(temp+1,data+7,4);

        temp1.x=(float)temp[0]/1000.0f;
        temp1.y=(float)temp[1]/1000.0f;
        memcpy(&temp1.z,data+11,4);
        if(temp1.x>11||temp1.y>9||temp1.x<5||temp1.y<3)
            return;
        raw_correction_value=temp1;
        if(0)
        {
            pos_reset=0;
            correction_value.x=temp1.x-(float)gyro.x/1000.0f;
            correction_value.y=temp1.y-(float)gyro.y/1000.0f;
            //correction_value.z=temp1.z-current_pos.z;
        }
    }

    return;
}

void DMA_recieve(void)
{
    static uint8_t abab;
    if(dma_buffer[1]!=abab)
    {
        communciation_error_counter=0;
        abab=dma_buffer[1];
    }
    else
    {
        if(communciation_error_counter<255)
            communciation_error_counter++;
    }

    int i;
    for(i=0;i<29;i++)
    {
        if(dma_buffer[i]=='?'&&dma_buffer[i+1]=='!')
        {
            break;
        }
    }
    if(i<=14)
    {
        if(dma_buffer[i+15]!='!')
        {
            return;
        }
        else
        {
            for(int k=0;k<16;k++)
            {
                Rx_buffer[k]=dma_buffer[i+k];
            }
        }
    }
    else
    {
        if(dma_buffer[i-15]!='!')
        {
            return;
        }
        else
        {
            for(int k=0;k<16;k++)
            {
                if(i+k<30)
                    Rx_buffer[k]=dma_buffer[i+k];
                else
                    Rx_buffer[k]=dma_buffer[k-(30-i)];
            }
            __ASM("nop");
        }
    }

    update_target_info(Rx_buffer);
    return;
}

void tof_recieve()
{
    if(__HAL_UART_GET_FLAG(&huart2,UART_FLAG_ORE) != RESET)
    {
        __HAL_UART_CLEAR_OREFLAG(&huart2);
    }
    uint8_t buffer[4]={0};
    int i=0;
    for(;i<10;i++)
    {
        if(tof_buffer[i]==0x59)
        {
            break;
        }
    }
    if(i==9&&tof_buffer[i]!=0x59) return;

    for(int k=0;k<4;k++)
    {
        buffer[k]=tof_buffer[i];
        if(k==1&&tof_buffer[i]!=0x59)
            return;
        if(i==9)
            i=0;
        else
            i++;

    }

    if(*((short*)(buffer+2))<=1000&&*((short*)(buffer+2))>=0)
        tof_read=*((short*)(buffer+2))/0.88f;
    else
        tof_read=0;
    return;
}

void tof_speed_control(void)
{
    // if(tof_read==0)
    //     return;
    float R=0,distance=0,maxspeed,speed;
    if(block_num<7)
    {
        R=0.5f*(0.5f-(block_num-2)*0.075f);
    }
    else
    {
        R=0.5f*(0.5f-(block_num-5-2)*0.075f);
    }
    if(block_color==forward||block_color==backward)
    {
        R=0.5f*(0.5f-(6-2)*0.075f);
    }
    //distance=tof_read/1000.0f+R;

    barrier *b=find_barrier(block_num);
    if(b==NULL)
        return;
    distance=(sqrt(pow(b->location.x-current_pos.x,2)+pow(b->location.y-current_pos.y,2))-0.1f);

    if(distance>=0.6f&&distance<2.5f)
    {
        maxspeed=sqrt(2*4*(distance-0.6f)+0.3f*0.3f);
    }
    else if(distance<0.6f&&distance>0)
    {
        maxspeed=0.3f;
    }
    else
    {
        maxspeed=114514;
    }
    speed=sqrt(dX*dX+dY*dY);

    float temp;
    if(speed>maxspeed&&(flags[hook_pos]==release||(flags[hook_status]==moving&&flags[hook_pos]==grasp))&&find_barrier(block_num)!=NULL)
    {
        if(dX!=0&&dY!=0)
        {
            temp=dX/speed*maxspeed;
            dY=dY/speed*maxspeed;
            dX=temp;
        }
    }
    return;
}

float *Fifo_update(float num1,float num2,float num3,float num4,int retnum)
{
    static float buffer[10][4];
    for(int i=8;i>=0;i--)
    {
        buffer[i+1][0]=buffer[i][0];
        buffer[i+1][1]=buffer[i][1];
        buffer[i+1][2]=buffer[i][2];
        buffer[i+1][3]=buffer[i][3];
    }
    buffer[0][0]=num1;
    buffer[0][1]=num2;
    buffer[0][2]=num1;
    buffer[0][3]=num1;
    return buffer[retnum];
}
/* USER CODE END 4 */

void HAL_TIM_PeriodElapsedCallback(TIM_HandleTypeDef *htim)
{
  /* USER CODE BEGIN Callback 0 */
    static int log_clock=0;
  /* USER CODE END Callback 0 */
  if (htim->Instance == TIM14) {
    HAL_IncTick();
  }
  /* USER CODE BEGIN Callback 1 */
	else if(htim->Instance == TIM6)	/**/
	{
		static uint8_t ID=2,flag_sendlog=0;
        if(flags[auto_drive_status]!=moving)
            tof_speed_control();

        check_dead_barrier();
        if(global_clock<1499&&thread_lock==0)
            global_clock++;
        if(flags[auto_drive_status]==moving&&global_clock<500)
        {
            executive_auto_move();
            send_log3(fabs(current_pos.x-pos_plan[global_clock].x),fabs(current_pos.y-pos_plan[global_clock].y),global_clock,99,&huart8);
//            if(global_clock%8==0)
//                send_log(ID,current_pos.x,current_pos.y,pos_plan[global_clock].x,pos_plan[global_clock].y,&huart3);
            flag_sendlog=0;
        }
        if(flags[auto_drive_status]!=moving&&flags[auto_drive_status]!=stop&&flag_sendlog==0)
        {
            ID++;
            flag_sendlog=1;
        }
        acceration_limit();
        Set_Pos();
//        Elmo_Run();
        if(log_clock==100)
        {
            //send_log2(sqrt(pow(current_pos.x-pos_log[global_clock].x,2)+pow(current_pos.y-pos_log[global_clock].y,2)),dX,current_speed.y,dY,&huart3);
            log_clock=0;
        }
        log_clock++;
//        GM6020_Set_Speed(0,1);
        extern GM6020_PID GM6020_Pos_Pid[8];
        //send_log2(current_speed.x,current_speed.y,0,0,&huart8);
        //VESC_COMMAND_SEND(&hfdcan2,3,1,(int)debug.x);
        if(flags[auto_drive_status]!=moving)
        {
            dX=0;
            dY=0;
        }

//        send_debug_msg(&huart8,0,0,0);
//        if(fabs(dX)>2.0f)
//            send_log(0x03,dX,Read_Rocker(0),Read_Rocker(1),0,&huart3);

	}
	else if(htim->Instance == TIM7)
	{
        speed_clock++;
        if(speed_clock==10)
            DMA_recieve();
        if(speed_clock==11)
            tof_recieve();
        if(speed_clock==49)
        {
            for(int i=38;i>=0;i--)
            {
                pos_log[i+1].x=pos_log[i].x;
                pos_log[i+1].y=pos_log[i].y;
                pos_log[i+1].z=pos_log[i].z;
            }
            pos_log[0].x=current_pos.x;
            pos_log[0].y=current_pos.y;
            pos_log[0].z=current_pos.z;
            send_msg();
        }
         if(speed_clock==50)
            speed_clock=0;

        speed_timer++;
	}
    else if(htim->Instance == TIM16)
    {

    }
  /* USER CODE END Callback 1 */
}

void Error_Handler(void)
{
  __disable_irq();
  while (1)
  {
  }
}

/************************ (C) COPYRIGHT STMicroelectronics *****END OF FILE****/

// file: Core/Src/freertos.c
/* USER CODE BEGIN Header */
/**
  ******************************************************************************
  * File Name          : freertos.c
  * Description        : Code for freertos applications
  ******************************************************************************
  * @attention
  *
  * <h2><center>&copy; Copyright (c) 2022 STMicroelectronics.
  * All rights reserved.</center></h2>
  *
  * This software component is licensed by ST under Ultimate Liberty license
  * SLA0044, the "License"; You may not use this file except in compliance with
  * the License. You may obtain a copy of the License at:
  *                             www.st.com/SLA0044
  *
  ******************************************************************************
  */
/* USER CODE END Header */

#include "FreeRTOS.h"
#include "task.h"
#include "main.h"
#include "cmsis_os.h"

/* USER CODE BEGIN Includes */
#include "user_task.h"
#include "my_robot.h"
#include "nrf.h"
#include "math.h"
#include "fdcan_bsp.h"
#include "move.h"
#include "Tinn.h"
#include "rgb.h"
#include "arm_math.h"
#include "VESC_CAN.h"
#include "Remote_Control.h"
#include "semphr.h"
/* USER CODE END Includes */

/* USER CODE BEGIN Variables */
uint8_t flags[20]={0}; //标志位区
uint8_t backup_flags[20]={0};//备份标志位区
mission_queue *mission_queue_head=NULL;//任务队列队头
mission_queue *backup_mission_queue_head=NULL;//备份任务队列队头
uint8_t task_reset=0;
uint8_t block_num=0;//计数器
uint8_t backup_block_num=0;//备份计数器
mission_queue *running_task;
extern Ort debug;
uint8_t get_block_flag=0;
uint8_t focus_mode=0;
uint8_t lock_status=0;
extern Tinn velocity_nn_x,velocity_nn_y;
SemaphoreHandle_t fdcan_queue_mutex;
Ort additional_vel;
/* USER CODE END Variables */
/* Definitions for defaultTask */
osThreadId_t defaultTaskHandle;
const osThreadAttr_t defaultTask_attributes = {
  .name = "defaultTask",
  .stack_size = 128 * 4,
  .priority = (osPriority_t) osPriorityNormal,
};
/* Definitions for Robot */
osThreadId_t RobotHandle;
const osThreadAttr_t Robot_attributes = {
  .name = "Robot",
  .stack_size = 256 * 4,
  .priority = (osPriority_t) osPriorityNormal,
};
/* Definitions for manualmove */
osThreadId_t manualmoveHandle;
const osThreadAttr_t manualmove_attributes = {
  .name = "manualmove",
  .stack_size = 256 * 4,
  .priority = (osPriority_t) osPriorityLow,
};
/* Definitions for error_detector */
osThreadId_t error_detectorHandle;
const osThreadAttr_t error_detector_attributes = {
  .name = "error_detector",
  .stack_size = 128 * 4,
  .priority = (osPriority_t) osPriorityLow,
};
/* Definitions for debug_msg */
osThreadId_t debug_msgHandle;
const osThreadAttr_t debug_msg_attributes = {
  .name = "debug_msg",
  .stack_size = 128 * 4,
  .priority = (osPriority_t) osPriorityLow,
};

/* USER CODE BEGIN FunctionPrototypes */
void add_mission(int mission_name,uint8_t *request,uint8_t flag_nessary,Ort *info);//任务添加函数
void task_handler(void *task_info);//任务执行函数
void save_status(void);
void load_status(void);
void manual_assistant(void);
/* USER CODE END FunctionPrototypes */

void StartDefaultTask(void *argument);
void RobotTask(void *argument);
void manual_move(void *argument);
void errordetector(void *argument);
void send_debug_msg(void *argument);

void MX_FREERTOS_Init(void); /* (MISRA C 2004 rule 8.1) */

void MX_FREERTOS_Init(void) {

  /* Create the thread(s) */
  /* creation of defaultTask */
  defaultTaskHandle = osThreadNew(StartDefaultTask, NULL, &defaultTask_attributes);

  /* creation of Robot */
  RobotHandle = osThreadNew(RobotTask, NULL, &Robot_attributes);

  /* creation of manualmove */
  manualmoveHandle = osThreadNew(manual_move, NULL, &manualmove_attributes);

  /* creation of error_detector */
  error_detectorHandle = osThreadNew(errordetector, NULL, &error_detector_attributes);

  /* creation of debug_msg */
  debug_msgHandle = osThreadNew(send_debug_msg, NULL, &debug_msg_attributes);

}

void StartDefaultTask(void *argument)
{
  /* USER CODE BEGIN StartDefaultTask */
    mission_queue *task_temp,*task_temp2;
    int flag_task_unavailable=0;
    TaskHandle_t *task_handle_temp;
    fdcan_queue_mutex=xSemaphoreCreateMutex();
  /* Infinite loop */
  for(;;)
  {
    if(fabs(dZ+current_pos.z)>180)
      flags[deg_offset]=360-fabs(dZ+current_pos.z);
    else
      flags[deg_offset]=fabs(dZ+current_pos.z);

    if(mission_queue_head!=NULL)
      {
          task_temp=mission_queue_head;
          do
          {
              for(int i=0;i<total_flags;i++)
              {
                  if(task_temp->request[i]!=flags[i]&&task_temp->request[i]!=either)
                  {
                      if(i==deg_offset)
                      {
                          if(flags[deg_offset]<task_temp->request[deg_offset])
                          {
                              continue;
                          }
                      }
                      flag_task_unavailable=1;
                      break;
                  }
              }
              if(flag_task_unavailable==0)
              {
                  task_handle_temp=(TaskHandle_t*)malloc(sizeof(TaskHandle_t));
                  task_temp->handle=task_handle_temp;
                  if(task_temp->taskname==autodrivelongdistance)
                  {
                      xTaskCreate(task_handler,"abab",30000,(void*)task_temp,(osPriority_t) osPriorityHigh,task_handle_temp);
                  }
                  else
                      xTaskCreate(task_handler,"abab",0x100,(void*)task_temp,(osPriority_t) osPriorityNormal,task_handle_temp);
                  if(task_temp==mission_queue_head)
                  {
                      mission_queue_head=mission_queue_head->next;
                      break;
                  }
                  else
                  {
                      task_temp2=mission_queue_head;
                      while(task_temp2->next!=task_temp)
                      {
                          task_temp2=task_temp2->next;
                      }
                      task_temp2->next=task_temp->next;
                      break;
                  }
              }
              else if(task_temp->flag_necessary==1)
              {
                  flag_task_unavailable=0;
                  break;
              }
              flag_task_unavailable=0;
              task_temp=task_temp->next;
          }while(task_temp!=NULL);
      }
    osDelay(2);
  }
  /* USER CODE END StartDefaultTask */
}

void RobotTask(void *argument)
{
  /* USER CODE BEGIN RobotTask */
    uint8_t set_flags[20]={either};
    uint8_t last_key_status[29]={0};
    Ort info={.x=0,.y=0,.z=0};
    int count=0,last_target_id=0;
    TaskHandle_t task_handle_temp;
    uint8_t msg=0;
    xTaskCreate(send_msg_synchronal,"kksk",100,&msg,osPriorityNormal,&task_handle_temp);
    barrier *target,target_temp,*target_temp_temp;
    /* Infinite loop */
    for(;;)
    {
        instruction_refresh();
        if(Read_Button(0)==1&&last_key_status[0]==0)
        {
    //          info.x=1;
    //          add_mission(0,set_flags,0,&info);
            set_flags[deg_offset]=5;
            target_temp_temp=find_barrier(block_num);
            if(target_temp_temp!=NULL)
            {
                dZ=-atan2f(target_temp_temp->location.x-current_pos.x,target_temp_temp->location.y-current_pos.y)*180.0f/3.1415926f;
                info.z=moving_complete1;
                add_mission(FUCKBLOCK,set_flags,1,&info);

            }
            last_key_status[0]=1;
        }
        else if(Read_Button(1)==1&&last_key_status[1]==0)
        {

            info.x=block_num;
//            info.y=8.4f;
//            info.z=moving_complete2;
            add_mission(AUTOPICKUPLONG,set_flags,1,&info);
    //          dZ=180;
            last_key_status[1]=1;
        }
        else if(Read_Button(2)==1&&last_key_status[2]==0)
        {
            if(flags[grab_pos]>1)
                info.x=flags[grab_pos]-1;
            add_mission(GRABPOSSET,set_flags,1,&info);
            last_key_status[2]=1;
        }
        else if(Read_Button(3)==1&&last_key_status[3]==0)
        {
            if(flags[grab_pos]<6)
                info.x=flags[grab_pos]+1;
            add_mission(GRABPOSSET,set_flags,1,&info);
            last_key_status[3]=1;
        }
        else if(Read_Button(4)==1&&last_key_status[4]==0)
        {
    //          if(flags[regulator_horizontal_pos]==backward)
    //          {
    //              info.x=up;
    //              info.y=forward;
    //              info.z=-1;
    //          }
    //          else
    //          {
    //              info.x=down;
    //              info.y=backward;
    //              info.z=-1;
    //          }
            if(flags[regulator_R_pos]==sweep)
            {
                info.z=flags[regulator_L_pos];
            }
            else
            {
                info.z=sweep;
            }
            add_mission(POSREGULATORPOSSET,set_flags,0,&info);
            last_key_status[4]=1;
        }
        else if(Read_Button(5)==1&&last_key_status[5]==0)
        {
            if(flags[regulator_L_pos]==regulate)
            {
                info.x=-1;
                info.y=-1;
                info.z=standby;
            }
            else
            {
                info.x=-1;
                info.y=-1;
                info.z=regulate;
            }
            add_mission(POSREGULATORPOSSET,set_flags,0,&info);
            last_key_status[5]=1;
        }
        else if(Read_Button(6)==1&&last_key_status[6]==0)
        {
            add_mission(2,set_flags,0,&info);
            last_key_status[6]=1;
        }
        else if(Read_Button(7)==1&&last_key_status[7]==0)
        {
            add_mission(3,set_flags,0,&info);
            last_key_status[7]=1;
        }
        else if(Read_Button(8)==1&&last_key_status[8]==0)
        {
            info.x=up;
            add_mission(4,set_flags,0,&info);
            last_key_status[8]=1;
        }
        else if(Read_Button(9)==1&&last_key_status[9]==0)
        {
            info.x=forward;
            add_mission(4,set_flags,0,&info);
            last_key_status[9]=1;
        }
        else if(Read_Button(10)==1&&last_key_status[10]==0)
        {
            info.x=down;
            add_mission(4,set_flags,0,&info);
            last_key_status[10]=1;
        }
        else if(Read_Button(11)==1&&last_key_status[11]==0)
        {
            mission_queue_head=NULL;
            last_key_status[11]=1;
        }
        else if(Read_Button(12)==1&&last_key_status[12]==0&&flags[lock_mode_status]==stop)
        {
            info.x=block_num;
            get_block_flag=1;
            dZ=-atan2f(target->location.x-current_pos.x,target->location.y-current_pos.y)*180.0f/3.1415926f;
            set_flags[deg_offset]=30;
            add_mission(AUTOPICKUP,set_flags,0,&info);
            focus_mode=0;
            last_key_status[12]=1;
        }
        else if(Read_Button(13)==1&&last_key_status[13]==0)
        {
            mission_queue_head=NULL;
            info.x=tower_bottom;
            add_mission(GRABPOSSET,set_flags,0,&info);
            info.x=block_num;
            add_mission(PICKUPACTIVATORPOSSET,set_flags,0,&info);
            info.x=up;
            add_mission(SWITCHERDIRECTIONSET,set_flags,0,&info);
            info.x=0;
            info.z=standby;
            add_mission(POSREGULATORPOSSET,set_flags,0,&info);
            get_block_flag=0;
            last_key_status[13]=1;
        }
        else if(Read_Button(14)==1&&last_key_status[14]==0)
        {
            extern float short_drive_deadzone;
            //flags[auto_drive_status]=moving;
            short_drive_deadzone=0.10f;
            info.x=current_pos.x+1.5f;
            info.y=current_pos.y+1.5f;
            info.z=moving_partially_complete1;
            add_mission(AUTODRIVESHORTDISTANCE,set_flags,0,&info);
            set_flags[auto_drive_status]=moving_partially_complete1;
            info.x=current_pos.x+1.5f;
            info.y=current_pos.y;
            info.z=moving_partially_complete2;
            add_mission(AUTODRIVESHORTDISTANCE,set_flags,0,&info);
            set_flags[auto_drive_status]=moving_partially_complete2;
            info.x=current_pos.x;
            info.y=current_pos.y;
            info.z=moving_partially_complete3;
            add_mission(AUTODRIVESHORTDISTANCE,set_flags,0,&info);
            last_key_status[14]=1;
        }
        else if(Read_Button(15)==1&&last_key_status[15]==0)//全局重启
        {
            __disable_irq();//关闭总中断
            NVIC_SystemReset();//请求单片机重启
            last_key_status[15]=1;
        }
        else if(Read_Button(16)==1&&last_key_status[16]==0)
        {
            if(flags[activator_pos]<6)
                info.x=flags[activator_pos]+1;
            add_mission(PICKUPACTIVATORPOSSET,set_flags,0,&info);
            last_key_status[16]=1;
        }
        else if(Read_Button(17)==1&&last_key_status[17]==0)
        {
            if(block_num<11)
                block_num++;
            last_key_status[17]=1;
        }
        else if(Read_Button(18)==1&&last_key_status[18]==0)
        {
            if(flags[activator_pos]>1)
                info.x=flags[activator_pos]-1;
            add_mission(PICKUPACTIVATORPOSSET,set_flags,0,&info);
            last_key_status[18]=1;
        }
        else if(Read_Button(19)==1&&last_key_status[19]==0)
        {
            if(block_num>2)
                block_num--;
            last_key_status[19]=1;
        }
        else if(Read_Button(20)==1&&last_key_status[20]==0)
        {
            if(focus_mode==1)
                focus_mode=0;
            else
                focus_mode=1;
            last_key_status[20]=1;
        }
        else if(Read_Button(21)==1&&last_key_status[21]==0&&flags[lock_mode_status]==stop&&flags[hook_pos]==grasp)
        {
            add_mission(AUTOPLACE,set_flags,0,&info);
            focus_mode=0;
            last_key_status[21]=1;
        }
        else if(Read_Button(26)==1&&last_key_status[26]==0)
        {

            last_key_status[26]=1;
        }
        else if(Read_Button(27)==1&&last_key_status[27]==0)
        {
            //info.x=block_num;
            //add_mission(AUTOPICKUPLONG,set_flags,0,&info);
            last_key_status[27]=1;
        }

        if(HAL_GPIO_ReadPin(GPIOB,GPIO_PIN_5)&&flags[regulator_R_pos]==sweep)
        {
            info.x=100;
            add_mission(TASKQUEUEDELAY,set_flags,0,&info);
            set_flags[delay_status]=delay_complete;
            info.z=standby;
            flags[regulator_R_pos]=standby;
            add_mission(POSREGULATORPOSSET,set_flags,0,&info);
        }

        for(int i=0;i<total_flags;i++)
        {
            set_flags[i]=either;
        }
        for(int i=0;i<=28;i++)
        {
            if(Read_Button(i)==0&&last_key_status[i]==1)
            {
                last_key_status[i]=0;
            }
        }
        //task_reset=Read_Button(14);

        target=find_barrier(block_num);
        if(HAL_GPIO_ReadPin(GPIOA,GPIO_PIN_1)||HAL_GPIO_ReadPin(GPIOA,GPIO_PIN_0))
        {

                extern uint16_t RGB_DEFAULT[2];
                RGB_DEFAULT[0]=30;
                RGB_Color(&htim8,TIM_CHANNEL_3,RGB_DEFAULT,0.2f);
        }
        else if(HAL_GPIO_ReadPin(GPIOB,GPIO_PIN_9))
        {
                extern uint16_t RGB_DEFAULT[2];
                RGB_DEFAULT[0]=180;
                RGB_Color(&htim8,TIM_CHANNEL_3,RGB_DEFAULT,0.2f);
    //          if(activator_flag==0)
    //          {
    //            add_mission(HOOKGRASP,set_flags,0,&info);
    //              activator_flag=1;
    //          }
        }
        else if(HAL_GPIO_ReadPin(GPIOB,GPIO_PIN_5))
        {
            extern uint16_t RGB_DEFAULT[2];
                RGB_DEFAULT[0]=0;
                RGB_Color(&htim8,TIM_CHANNEL_3,RGB_DEFAULT,1.0f);
        }
        else
        {
            extern uint16_t RGB_DEFAULT[2];
            RGB_DEFAULT[0]=270;
            RGB_Color(&htim8,TIM_CHANNEL_3,RGB_DEFAULT,0.2f);
        }

        if((HAL_GPIO_ReadPin(GPIOB,GPIO_PIN_9))&&get_block_flag!=1)
        {
            if(HAL_GPIO_ReadPin(GPIOB,GPIO_PIN_9))
            {
                focus_mode=0;
                if(get_block_flag==0)
                    pick_up(target->location.z,manualmode,0);
                else
                    pick_up(target->location.z,manualmode,1);
                get_block_flag=1;
            }
        }
        if(target!=NULL)
        {
    //          debug.x=fabs(current_pos.z-atan2f(target->location.x-current_pos.x,target->location.y-current_pos.y)*180.0f/3.1415926f);
    //          debug.y=fabs(sqrt(pow(current_pos.x-target->location.x,2)+pow(current_pos.y-target->location.y,2))-0.595f);
            //((fabs(sqrt(pow(current_pos.x-target->location.x,2)+pow(current_pos.y-target->location.y,2))-114.595f)<0.05f&&target->last_update_time<=500&&flags[auto_drive_status]!=moving)||

            if(fabs(current_pos.z-atan2f(target->location.x-current_pos.x,target->location.y-current_pos.y)*180.0f/3.1415926f)<50.0f
                &&(pow(target->location.x-current_pos.x,2)+pow(target->location.y-current_pos.y,2)<2.3f)
                &&get_block_flag==0&&target->last_update_time<300
                &&flags[grab_pos]==tower_bottom&&flags[grab_status]==stop)
            {
                if(target->location.z==forward||target->location.z==backward)
                {
                    info.x=block_num+5;
                    if(block_num>6)
                        info.x-=5;
                    add_mission(GRABPOSSET,set_flags,0,&info);
                    info.x=tower_block_5;
                    add_mission(PICKUPACTIVATORPOSSET,set_flags,0,&info);
                    info.x=forward;
                    add_mission(SWITCHERDIRECTIONSET,set_flags,0,&info);
                    info.z=regulate;
                    set_flags[grab_status]=stop;
                    add_mission(POSREGULATORPOSSET,set_flags,0,&info);
                    get_block_flag=2;
                }
    //              else
    //                  get_block_flag=3;
            }
        }
        extern PID_T pid_deg;
        static int lock_flag=0;
        //debug.x=((arm_sin_f32(current_pos.z*3.1415926f/180.f)*(target->location.x-current_pos.x)+arm_cos_f32(current_pos.z*3.1415926f/180.f)*(target->location.y-current_pos.y))/sqrt(pow(target->location.x-current_pos.x,2)+pow(target->location.y-current_pos.y,2)));
        //debug.y=pow(target->location.x-current_pos.x,2)+pow(target->location.y-current_pos.y,2);
        debug.x=target->deg;
        debug.y=-target->deg+current_pos.z;
        if(debug.y>90)
            debug.y-=180;
        if(debug.y<-90)
            debug.y+=180;
        if(target!=NULL&&focus_mode==1&&((arm_sin_f32(current_pos.z*3.1415926f/180.f)*(target->location.x-current_pos.x)+arm_cos_f32(current_pos.z*3.1415926f/180.f)*(target->location.y-current_pos.y))/sqrt(pow(target->location.x-current_pos.x,2)+pow(target->location.y-current_pos.y,2)))>0.766f&&pow(target->location.x-current_pos.x,2)+pow(target->location.y-current_pos.y,2)<5.76f&&target->last_update_time<300)
        {
            lock_status=1;
            if(last_target_id!=target->barrier_ID)
            {
                target_temp=*target;
                last_target_id=target->barrier_ID;
            }
            if(count>10&&lock_flag==1)
            {
                target_temp=*target;
                count=0;
            }
            else if(lock_flag==0&&count>25)
            {
                target_temp=*target;
                count=0;
                lock_flag=1;
            }
            if(pow(target_temp.location.x-current_pos.x,2)+pow(target_temp.location.y-current_pos.y,2)>0.09f)
                dZ=-atan2f(target_temp.location.x-current_pos.x,target_temp.location.y-current_pos.y)*180.0f/3.1415926f;
            count++;
            pid_deg.PID_MAX=75.0f;
            manual_assistant();
            if(target->deg==90||fabs(target->deg)<5)
            {
                additional_vel.x=0;
                additional_vel.y=0;
            }
        }
        else
        {
            pid_deg.PID_MAX=200.0f;
            lock_flag=0;
            lock_status=0;
            additional_vel.x=0;
            additional_vel.y=0;
        }

    osDelay(10);
  }
  /* USER CODE END RobotTask */
}

void manual_move(void *argument)
{
  /* USER CODE BEGIN manual_move */

  /* Infinite loop */
  for(;;)
  {
          instruction_refresh();
      if(((Read_Rocker(1)*Read_Rocker(1)+Read_Rocker(0)*Read_Rocker(0))>=100||(Read_Rocker(2)*Read_Rocker(2)+Read_Rocker(3)*Read_Rocker(3))>=100)&&flags[auto_drive_status]!=moving)
      {
        flags[0]=manualmode;
        static int rocker[4]={0};
        if((Read_Rocker(1)*Read_Rocker(1)+Read_Rocker(0)*Read_Rocker(0))>=100&&abs(Read_Rocker(1))<=190&&abs(Read_Rocker(0))<=190)
        {
            rocker[0]=Read_Rocker(0);
            rocker[1]=Read_Rocker(1);
        }
        else
        {
            rocker[0]=0;
            rocker[1]=0;
        }
        dX=(0.00005876f*rocker[0]*rocker[0]*rocker[0]+0.2471129f*rocker[0])/90.0f;
        dY=(0.00005876f*rocker[1]*rocker[1]*rocker[1]+0.2471129f*rocker[1])/90.0f;
        if((Read_Rocker(2)*Read_Rocker(2)+Read_Rocker(3)*Read_Rocker(3))>=100&&abs(Read_Rocker(2))<=190&&abs(Read_Rocker(3))<=190)
        {
            rocker[2]=-Read_Rocker(2);
            rocker[3]=-Read_Rocker(3);
            if(lock_status==0)
                dZ+=rocker[2]/700.0f;
            else
            {
                if(abs(rocker[2])<120&&(Read_Rocker(1)*Read_Rocker(1)+Read_Rocker(0)*Read_Rocker(0))<=100)
                {
                    dX+=-rocker[2]/90.0f*arm_cos_f32(current_pos.z*3.1415926f/180.0f);
                    dY+=rocker[2]/90.0f*arm_sin_f32(current_pos.z*3.1415926f/180.0f);
                    dX+=additional_vel.x;
                    dY+=additional_vel.y;
                }
                else
                {
                    dX+=-rocker[2]/90.0f*arm_cos_f32(current_pos.z*3.1415926f/180.0f);
                    dY+=rocker[2]/90.0f*arm_sin_f32(current_pos.z*3.1415926f/180.0f);
                }
            }
            if(dZ>=180)
            {
                dZ-=360.0f;
            }
            if(dZ<=-180)
            {
                dZ+=360.0f;
            }
        }
        else
        {
            rocker[2]=0;
            rocker[3]=0;
        }

        dX+=-rocker[3]/90.0f*arm_sin_f32(current_pos.z*3.1415926f/180.0f);
        dY+=-rocker[3]/90.0f*arm_cos_f32(current_pos.z*3.1415926f/180.0f);
//        if(Read_Button(22)==1)
//        {
//            dX/=10;
//            dY/=10;
//        }

      }

    osDelay(1);
  }
  /* USER CODE END manual_move */
}

void errordetector(void *argument)
{
  /* USER CODE BEGIN errordetector */
    uint8_t system_status[10];
    uint8_t transmit_buffer[8]={0};
    uint8_t temp=0;
  /* Infinite loop */
  for(;;)
  {
      if(block_color==up)
        system_status[0]=1;//1bit
      else
        system_status[0]=0;
      if(communciation_error_counter==255)
        system_status[1]=1;
      else
          system_status[1]=0;
      system_status[2]=flags[grab_status];
      if(gyro.error_counter==1000)
          system_status[3]=1;
      else
          system_status[3]=0;
      system_status[4]=flags[regulator_status];
//      system_status[5]=flags[activator_status];
      system_status[5]=deg_pid_disable;
      system_status[6]=focus_mode;
      if(block_num<7)//right(0) or left(1)
          system_status[7]=0;
      else
          system_status[7]=1;
      temp=0;
      for(int i=0;i<8;i++)
      {
          temp=temp|(system_status[i]<<i);
      }
      transmit_buffer[0]=temp;
      if(block_num<7)
          system_status[0]=7-block_num;//3bit
      else
          system_status[0]=12-block_num;//3bit
      for(int i=1;i<=4;i++)
      {
          if(VESC_Feedback[i].error_flag==1)
          {
              system_status[1]=1;//1bit
              break;
          }
          else
              system_status[1]=0;
      }
      system_status[2]=flags[auto_drive_status];//4bit
      temp=0;
      temp=temp|(system_status[0]<<5);
      temp=temp|(system_status[1]<<4);
      temp=temp|(system_status[2]);
      transmit_buffer[1]=temp;
      transmit_buffer[2]=(uint8_t)(current_pos.x*16.0f);
      transmit_buffer[3]=(uint8_t)(current_pos.y*16.0f);
      transmit_buffer[4]=(current_pos.z+180)/2;
      transmit_buffer[5]=(uint8_t)(fabs(current_speed.x)*32.0f);
      transmit_buffer[6]=(uint8_t)(fabs(current_speed.y)*32.0f);
      for(int i=0;i<8;i++)
        nRF24L01_ack_pay.Ack_Buf[i]=transmit_buffer[i];
      Ack_load(7);
      osDelay(10);
  }
  /* USER CODE END errordetector */
}

void send_debug_msg(void *argument)
{
  /* USER CODE BEGIN send_debug_msg */
  /* Infinite loop */
  for(;;)
  {
    //   if(flags[auto_drive_status]==moving)
    //     send_log2(current_pos.x,current_pos.y,pos_plan[global_clock].x,pos_plan[global_clock].y,&huart3);
    if(fdcan_msg_queue_head!=NULL)
    {
        xSemaphoreTake(fdcan_queue_mutex,5);
        FDCAN_SendData(fdcan_msg_queue_head->fdcan,fdcan_msg_queue_head->msg,fdcan_msg_queue_head->ID,fdcan_msg_queue_head->len);
        fdcan_msg_queue *temp=fdcan_msg_queue_head;
        fdcan_msg_queue_head=fdcan_msg_queue_head->next;
        free(temp);
        xSemaphoreGive(fdcan_queue_mutex);
    }
    //send_log3()
    osDelay(20);
  }
  /* USER CODE END send_debug_msg */
}

/* USER CODE BEGIN Application */
void add_mission(int mission_name,uint8_t *request,uint8_t flag_nessary,Ort *info)//然后这里会添加任务
{
    mission_queue *temp,*searcher;
    temp=(mission_queue*)malloc(sizeof(mission_queue));
    switch(mission_name)//根据需要添加的任务的序号为结构体中的函数指针变量赋值，使用时可能需要频繁更改
    {
        case 0:{
            temp->taskname=grabposset;
            break;
        }
        case 1:{
            temp->taskname=autodirveshortdistance;
            break;
        }
        case 2:{
            temp->taskname=hookgrasp;
            break;
        }
        case 3:{
            temp->taskname=hookrelease;
            break;
        }
        case 4:{
            temp->taskname=switcherdirectionset;
            break;
        }
        case 5:{
            temp->taskname=catapultactivate;
            break;
        }
        case 6:{
            temp->taskname=autopickup;
            break;
        }
        case 7:{
            temp->taskname=autoplace;
            break;
        }
        case 8:{
            temp->taskname=autodrivelongdistance;
            break;
        }
        case 9:{
            temp->taskname=posregulatorposset;
            break;
        }
        case 10:{
            temp->taskname=pickupactivatorposset;
            break;
        }
        case 12:{
            temp->taskname=taskqueuedelay;
            break;
        }
        case 13:{
            temp->taskname=moveforward;
            break;
        }
        case 14:{
            temp->taskname=fuckblock;
            break;
        }
        case 15:{
            temp->taskname=autopickuplong;
            break;
        }
        case 16:{
            temp->taskname=moveforward2;
            break;
        }
    }
    temp->flag_necessary=flag_nessary;//决定是否为关键任务（不可跳过）
    temp->flag_finish=0;
    temp->next=NULL;
    temp->handle=NULL;
    temp->info.x=info->x;
    temp->info.y=info->y;
    temp->info.z=info->z;
    for(int i=0;i<total_flags;i++)
    {
        temp->request[i]=request[i];
    }
    if(mission_queue_head==NULL)
    {
        mission_queue_head=temp;
    }
    else
    {
        searcher=mission_queue_head;
        while(searcher->next!=NULL)
        {
            searcher=searcher->next;
        }
        searcher->next=temp;
    }
    return;
}

void save_status(void)
{
    for(int i=0;i<total_flags;i++)
    {
        backup_flags[i]=flags[i];
    }
    backup_mission_queue_head=mission_queue_head;
    backup_block_num=block_num;
    return;
}

void load_status(void)
{
    Ort info;
    TaskHandle_t temp;
    uint8_t setflags[20];
    for(int i=0;i<total_flags;i++)
    {
        setflags[i]=either;
    }
    task_reset=1;
    mission_queue_head=NULL;//暂定为清空任务队列
    temp=xTaskGetHandle("defaultTask");
    vTaskSuspend(temp);
    osDelay(100);
    for(int i=0;i<total_flags;i++)
    {
        flags[i]=backup_flags[i];
    }
    info.x=flags[grab_pos];
    add_mission(GRABPOSSET,setflags,0,&info);
    info.x=flags[switcher_pos];
    add_mission(SWITCHERDIRECTIONSET,setflags,0,&info);
    block_num=backup_block_num;
    for(int i=0;i<8;i++)
        cmd_feedback[i]=0;
    vTaskResume(temp);
    task_reset=0;
    return;
}

void task_handler(void *task_info)//条件满足的时候这里会开始执行任务，任务具体函数在user_task.c里面
{
    mission_queue *current_task=(mission_queue*)task_info;
    TaskHandle_t current_handle=*(current_task->handle);
    while(1)
    {
        if(current_task->flag_finish==0)
        {
            current_task->taskname(current_task);
        }
        else
        {
            free(current_task);
            vTaskDelete(current_handle);
        }
        if(task_reset==1)
        {
            free(current_task);
            for(int i=0;i<total_flags;i++)
                flags[i]=0;

            vTaskDelete(current_handle);
        }
        osDelay(10);
    }
}

float vector_mod(Ort abab)
{
    return my_sqrt(abab.x*abab.x+abab.y*abab.y);
}

extern int judge_sign(double num);

void manual_assistant(void)
{
    barrier *target;
    float deg,len;
    //Ort vec_deg1,vec_deg2,vec_tar,vel1,vel2,vel_out;
    target=find_barrier(block_num);
    if(target==NULL)
        return;
    deg=-target->deg+current_pos.z;
    if(deg>90)
        deg-=180;
    if(deg<-90)
        deg+=180;
    if(target->deg==361||deg==0||fabs(deg)<5)
    {
        return;
    }
    len=0.7f*arm_sin_f32(3.1415926f*fabs(deg)/60.0f);
    additional_vel.x=judge_sign(deg)*len*arm_cos_f32(current_pos.z*3.1415926f/180.0f);
    additional_vel.y=-judge_sign(deg)*len*arm_sin_f32(current_pos.z*3.1415926f/180.0f);
//    additional_vel.x+=-len/3.0f*arm_sin_f32(current_pos.z*3.1415926f/180.0f);
//    additional_vel.y+=-len/3.0f*arm_cos_f32(current_pos.z*3.1415926f/180.0f);
//    vec_deg1.x=-arm_sin_f32(deg*3.1415926f/180.0f);
//    vec_deg1.y=arm_cos_f32(deg*3.1415926f/180.0f);
//    vec_deg2.x=-vec_deg1.x;
//    vec_deg2.y=-vec_deg1.y;
//    vec_tar.x=0;
//    vec_tar.y=1;
//    vel1.x=vec_deg1.x-vec_tar.x;
//    vel1.y=vec_deg1.y-vec_tar.y;
//    vel2.x=vec_deg2.x-vec_tar.x;
//    vel2.y=vec_deg2.y-vec_tar.y;
//    if(vector_mod(vel1)>vector_mod(vel2))
//    {
//        vel_out=vel2;
//    }
//    else
//    {
//        vel_out=vel1;
//    }
//    len=vector_mod(vel_out);
//    vel_out.x=vel_out.x/len;
//    vel_out.y=vel_out.y/len;
//    len=arm_sin_f32(len*2.2214414690f);
//    vel_out.x*=len;
//    vel_out.y*=len;
//    dX=vel_out.x;
//    dY=vel_out.y;
    return;
}

void send_msg_synchronal(void *id)
{
    uint8_t ID=*(uint8_t*)id;
    uint8_t msg_buffer[16]={0};
    msg_buffer[0]='?';
    msg_buffer[1]='!';
    msg_buffer[2]=0xAA;
    if(block_num<7)
    {
        msg_buffer[3]=7-block_num;
    }
    else
    {
        msg_buffer[3]=21-block_num;
    }
    msg_buffer[15]='!';
    while(1)
    {
        if(block_num<7)
        {
            msg_buffer[3]=7-block_num;
        }
        else
        {
            msg_buffer[3]=21-block_num;
        }
        HAL_UART_Transmit(&huart8,msg_buffer,16,200);
        osDelay(20);
    }
    vTaskDelete(xTaskGetCurrentTaskHandle());
    return;
}
/* USER CODE END Application */

/************************ (C) COPYRIGHT STMicroelectronics *****END OF FILE****/
